# YT9218 register map
Vendor: Motorcomm; Series: YT921x; File version: 1.0
Registers are 32-bit, read-write, no defined reset value unless marked. A register's access mark holds for its fields unless they carry their own. Offsets are from the block's base; [hi:lo] are bit positions; lines under a group give offsets from that group; {n}, {i} and the like mark numbered series; 'fields as' and 'values as' point back to an identical list.

## ACL — ACL keys and control
Base 0x00200000
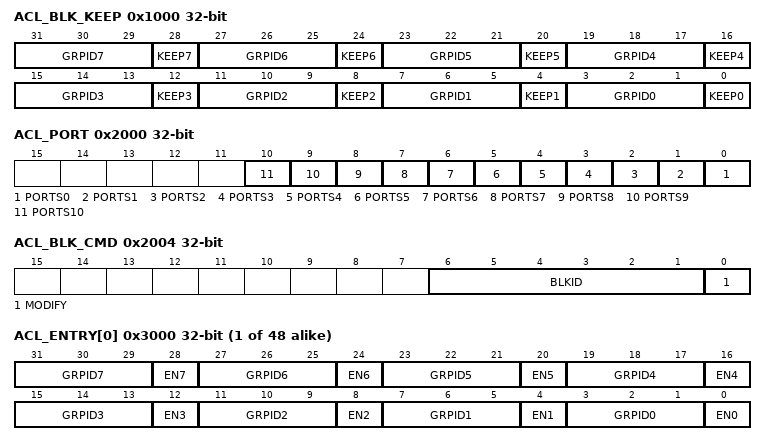
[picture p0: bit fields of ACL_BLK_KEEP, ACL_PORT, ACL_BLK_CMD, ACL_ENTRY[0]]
0x1000 ACL_BLK_KEEP — While a block is open, marks the key slots that the commit must leave unchanged.
  [4n+3:4n+1] GRPID{n} (n=0..7) — Group number for slot bin during the commit.
  [4n] KEEP{n} (n=0..7) — Slot bin keeps its current key and mask.
0x2000 ACL_PORT — Ports whose received frames are checked against the access control list.
  [n] PORTS{n} (n=0..10) — The access control list is applied to port port.
0x2004 ACL_BLK_CMD — Opens one ACL block for modification and commits it; see Writing a rule.
  [6:1] BLKID — Block number from 0 to 47.
  [0] MODIFY — Write 1 to open the block for writing. Write 0 to commit the changes.
{0x3000+4i} ACL_ENTRY[{i}] (i=0..47) — Enables the eight key slots of one block and groups slots into rules. Slots with the same group number must all match for the rule to hit; the group number is also the slot whose ACL_ACT entry holds the action. Index: blk = 0 to 47.
  [4n+3:4n+1] GRPID{n} (n=0..7) — Group number of slot bin. The slots of one rule share a group number.
  [4n] EN{n} (n=0..7) — Slot bin is in use.
{0x4000+0x200*i} ACL_KEY[{i}] (i=0..7) group — Value half of one key slot. Index blk is the block and bin the slot in the block. The layout of bits 35 to 0 and of the range flags depends on ACL_KEY.TYPE. Index: bin = 0 to 7; the member array index is blk.
  {0x0+8j} BLK[{j}] (j=0..47) group — One ACL_KEY entry; index blk = 0 to 47.
    0x00 W0 — ACL key slot: bits 31 to 0. Value half of one key slot. Index blk is the block and bin the slot in the block. The layout of bits 35 to 0 and of the range flags depends on ACL_KEY.TYPE.
    0x00 W0_MAC_ADDR0 (alternate view of W0) — ACL key slot, bits 31 to 0, layout for key types MAC_DA0, MAC_SA0: MAC address high 32 bits
      [31:0] ADDR — MAC address bytes 0 to 3. Byte 0 is in bits 31 to 24.
    0x00 W0_MAC_DA1_SA1 (alternate view of W0) — ACL key slot, bits 31 to 0, layout for key types MAC_DA1_SA1: MAC address low 16 bits of destination and source
      [31:16] MAC_DA1 — Destination MAC address bytes 4 and 5.
      [15:0] MAC_SA1 — Source MAC address bytes 4 and 5.
    0x00 W0_VLAN (alternate view of W0) — ACL key slot, bits 31 to 0, layout for key types VLAN: VLAN tags with tag format
      [31:30] CTAG_FMT — Customer tag format of the frame. The Linux driver gives no codes. The vendor SDK list yt_vlan_format_t gives 0 for untagged, 1 for priority-tagged and 2 for tagged.
      [29] SDEI — Drop eligible bit of the service tag.
      [28:26] SPRI — Priority of the service tag.
      [25:24] STAG_FMT — Service tag format of the frame. The Linux driver gives no codes. The vendor SDK list yt_vlan_format_t gives 0 for untagged, 1 for priority-tagged and 2 for tagged.
      [23:12] SVID — Service VLAN ID.
      [11:0] CVID — Customer VLAN ID.
    0x00 W0_VTAG (alternate view of W0) — ACL key slot, bits 31 to 0, layout for key types VTAG: VLAN tags
      [31] CDEI — Drop eligible bit of the customer tag.
      [30:28] CPRI — Priority of the customer tag.
      [27] SDEI — Drop eligible bit of the service tag.
      [26:24] SPRI — Priority of the service tag.
      [23:12] SVID — Service VLAN ID.
      [11:0] CVID — Customer VLAN ID.
    0x00 W0_IPV4 (alternate view of W0) — ACL key slot, bits 31 to 0, layout for key types IPV4_DA, IPV4_SA: IPv4 address
      [31:0] ADDR — IPv4 address. The first byte is in bits 31 to 24.
    0x00 W0_IPV6_ADDR0 (alternate view of W0) — ACL key slot, bits 31 to 0, layout for key types IPV6_DA0, IPV6_SA0: IPv6 address bits 127 to 96
      [31:0] ADDR — 32 bits of the IPv6 address. The most significant byte is in bits 31 to 24.
    0x00 W0_IPV6_ADDR1 (alternate view of W0) — ACL key slot, bits 31 to 0, layout for key types IPV6_DA1, IPV6_SA1: IPv6 address bits 95 to 64
      fields as ACL_KEY[0].BLK[0].W0_IPV6_ADDR0
    0x00 W0_IPV6_ADDR2 (alternate view of W0) — ACL key slot, bits 31 to 0, layout for key types IPV6_DA2, IPV6_SA2: IPv6 address bits 63 to 32
      fields as ACL_KEY[0].BLK[0].W0_IPV6_ADDR0
    0x00 W0_IPV6_ADDR3 (alternate view of W0) — ACL key slot, bits 31 to 0, layout for key types IPV6_DA3, IPV6_SA3: IPv6 address bits 31 to 0
      fields as ACL_KEY[0].BLK[0].W0_IPV6_ADDR0
    0x00 W0_MISC (alternate view of W0) — ACL key slot, bits 31 to 0, layout for key types MISC: IP header and TCP flags
      [30] PPPOE_FLAG — The frame carries PPPoE.
      [29] FIRST_FRAG — The packet is the first fragment.
      [28] IP_OPTION — The packet has IP options or extension headers.
      [27:20] TCP_FLAGS — TCP flags byte.
      [19:12] IP_PROTO — IP protocol number.
      [11:4] TOS — IPv4 type of service or IPv6 traffic class byte.
      [3:0] L3_TYPE — Layer 3 protocol class.
        0=OTHER (Any other protocol); 1=IPV4; 2=IPV6; 3=ARP; 4=LLDP; 5=PAE (IEEE 802.1X port access entity); 6=ERP (Ethernet ring protection. The meaning is inferred from the name; yt921x_acl_rule_ext_parse_flow_entries selects the value for the EtherType ETH_P_CFM.); 7=SLOW_PROTOCOL (IEEE 802.3 slow protocols such as LACP)
    0x00 W0_L4 (alternate view of W0) — ACL key slot, bits 31 to 0, layout for key types L4: Layer 4 ports
      [31:16] DPORT — Layer 4 destination port.
      [15:0] SPORT — Layer 4 source port.
    0x00 W0_UDF (alternate view of W0) — ACL key slot, bits 31 to 0, layout for key types UDF0, UDF1, UDF2, UDF3, UDF4, UDF5, UDF6, UDF7: User-defined fields
      [31:16] UDF0 — Two bytes from the even-numbered user-defined field window of the pair.
      [15:0] UDF1 — Two bytes from the odd-numbered user-defined field window of the pair.
    0x00 W0_ETHERTYPE (alternate view of W0) — ACL key slot, bits 31 to 0, layout for key types ETHERTYPE: EtherType
      [15:0] ETHERTYPE
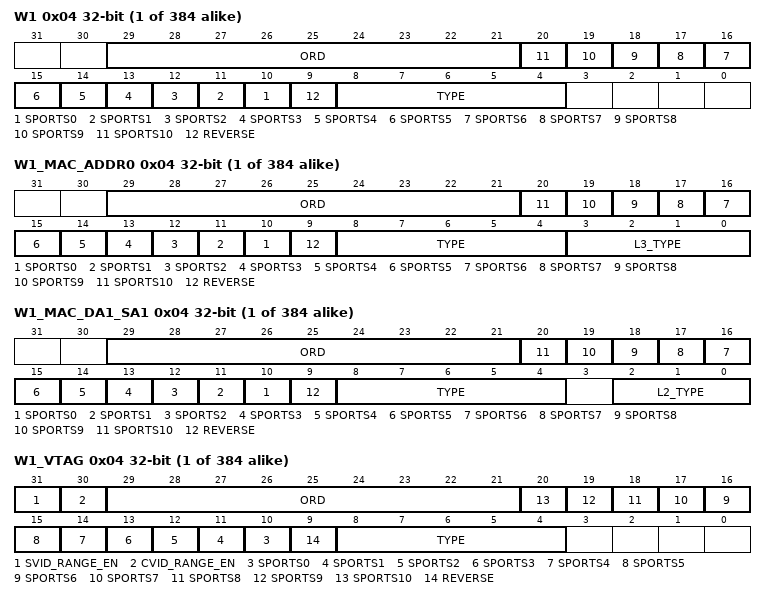
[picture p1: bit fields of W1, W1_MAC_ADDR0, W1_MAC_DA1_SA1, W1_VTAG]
    0x04 W1 — ACL key slot: bits 63 to 32. Value half of one key slot. Index blk is the block and bin the slot in the block. The layout of bits 35 to 0 and of the range flags depends on ACL_KEY.TYPE.
      [29:21] ORD — Order of the rule. When several rules match, the highest value wins.
      [n+10] SPORTS{n} (n=0..10) — Receiving ports the rule applies to. Each port has one bit.
      [9] REVERSE — The slot matches when the frame does not match the key.
      [8:4] TYPE — Key type. It selects the layout of the rest of the slot.
        0=NA (Slot not used); 1=MAC_DA0 (Destination MAC address bits 47 to 16); 2=MAC_SA0 (Source MAC address bits 47 to 16); 3=MAC_DA1_SA1 (Destination and source MAC address bits 15 to 0); 4=VLAN (VLAN identifiers and priorities with tag format); 5=VTAG (VLAN identifiers and priorities); 6=IPV4_DA (IPv4 destination address); 7=IPV4_SA (IPv4 source address); 8=IPV6_DA0 (IPv6 destination address bits 127 to 96); 9=IPV6_DA1 (IPv6 destination address bits 95 to 64); 10=IPV6_DA2 (IPv6 destination address bits 63 to 32); 11=IPV6_DA3 (IPv6 destination address bits 31 to 0); 12=IPV6_SA0 (IPv6 source address bits 127 to 96); 13=IPV6_SA1 (IPv6 source address bits 95 to 64); 14=IPV6_SA2 (IPv6 source address bits 63 to 32); 15=IPV6_SA3 (IPv6 source address bits 31 to 0); 16=MISC (IP and TCP header fields. The fields are the IP protocol and the type of service and the TCP flags and the frame class); 17=L4 (TCP or UDP source and destination ports); 18=UDF0 (User-defined field windows 0 and 1); 19=UDF1 (User-defined field windows 2 and 3); 20=UDF2 (User-defined field windows 4 and 5); 21=UDF3 (User-defined field windows 6 and 7); 22=UDF4 (User-defined field windows 8 and 9); 23=UDF5 (User-defined field windows 10 and 11); 24=UDF6 (User-defined field windows 12 and 13); 25=UDF7 (User-defined field windows 14 and 15); 26=ETHERTYPE
    0x04 W1_MAC_ADDR0 (alternate view of W1) — ACL key slot, bits 63 to 32, layout for key types MAC_DA0, MAC_SA0: MAC address high 32 bits
      [29:21] ORD — Order of the rule. When several rules match, the highest value wins.
      [n+10] SPORTS{n} (n=0..10) — Receiving ports the rule applies to. Each port has one bit.
      [9] REVERSE — The slot matches when the frame does not match the key.
      [8:4] TYPE — Key type. It selects the layout of the rest of the slot.
        values as ACL_KEY[0].BLK[0].W1.TYPE
      [3:0] L3_TYPE — Layer 3 protocol class.
        values as ACL_KEY[0].BLK[0].W0_MISC.L3_TYPE
    0x04 W1_MAC_DA1_SA1 (alternate view of W1) — ACL key slot, bits 63 to 32, layout for key types MAC_DA1_SA1: MAC address low 16 bits of destination and source
      [29:21] ORD — Order of the rule. When several rules match, the highest value wins.
      [n+10] SPORTS{n} (n=0..10) — Receiving ports the rule applies to. Each port has one bit.
      [9] REVERSE — The slot matches when the frame does not match the key.
      [8:4] TYPE — Key type. It selects the layout of the rest of the slot.
        values as ACL_KEY[0].BLK[0].W1.TYPE
      [2:0] L2_TYPE — Frame encapsulation.
        0=ETH (Other Ethernet framing. The meaning is inferred from the name.); 1=ETHV2 (Ethernet II); 2=ETHSAP (IEEE 802.3 with LLC); 3=ETHSNAP (IEEE 802.3 with LLC and SNAP)
    0x04 W1_VLAN (alternate view of W1) — ACL key slot, bits 63 to 32, layout for key types VLAN: VLAN tags with tag format
      [31] SVID_RANGE_EN — Match the service VLAN ID as a range. It is inferred from the two layer 4 port range flags, which yt921x_acl_rule_ext_parse_flow_entries uses, that the key holds the lowest and the mask the highest value.
      [30] CVID_RANGE_EN — Match the customer VLAN ID as a range. It is inferred from the two layer 4 port range flags, which yt921x_acl_rule_ext_parse_flow_entries uses, that the key holds the lowest and the mask the highest value.
      [29:21] ORD — Order of the rule. When several rules match, the highest value wins.
      [n+10] SPORTS{n} (n=0..10) — Receiving ports the rule applies to. Each port has one bit.
      [9] REVERSE — The slot matches when the frame does not match the key.
      [8:4] TYPE — Key type. It selects the layout of the rest of the slot.
        values as ACL_KEY[0].BLK[0].W1.TYPE
      [3] CDEI — Drop eligible bit of the customer tag.
      [2:0] CPRI — Priority of the customer tag.
    0x04 W1_VTAG (alternate view of W1) — ACL key slot, bits 63 to 32, layout for key types VTAG: VLAN tags
      [31] SVID_RANGE_EN — Match the service VLAN ID as a range. It is inferred from the two layer 4 port range flags, which yt921x_acl_rule_ext_parse_flow_entries uses, that the key holds the lowest and the mask the highest value.
      [30] CVID_RANGE_EN — Match the customer VLAN ID as a range. It is inferred from the two layer 4 port range flags, which yt921x_acl_rule_ext_parse_flow_entries uses, that the key holds the lowest and the mask the highest value.
      [29:21] ORD — Order of the rule. When several rules match, the highest value wins.
      [n+10] SPORTS{n} (n=0..10) — Receiving ports the rule applies to. Each port has one bit.
      [9] REVERSE — The slot matches when the frame does not match the key.
      [8:4] TYPE — Key type. It selects the layout of the rest of the slot.
        values as ACL_KEY[0].BLK[0].W1.TYPE
    0x04 W1_IPV4 (alternate view of W1) — ACL key slot, bits 63 to 32, layout for key types IPV4_DA, IPV4_SA: IPv4 address
      [30] ADDR_RANGE_EN — Match the address as a range. It is inferred from the two layer 4 port range flags, which yt921x_acl_rule_ext_parse_flow_entries uses, that the key holds the lowest and the mask the highest value.
      [29:21] ORD — Order of the rule. When several rules match, the highest value wins.
      [n+10] SPORTS{n} (n=0..10) — Receiving ports the rule applies to. Each port has one bit.
      [9] REVERSE — The slot matches when the frame does not match the key.
      [8:4] TYPE — Key type. It selects the layout of the rest of the slot.
        values as ACL_KEY[0].BLK[0].W1.TYPE
      [3] FRAG — The packet is an IP fragment.
      [2:0] L4_TYPE — Layer 4 protocol class.
        0=OTHER (Any other protocol); 1=TCP; 2=UDP; 3=UDPLITE; 4=ICMP; 5=IGMP; 6=MLD (Multicast Listener Discovery); 7=ND (IPv6 Neighbour Discovery)
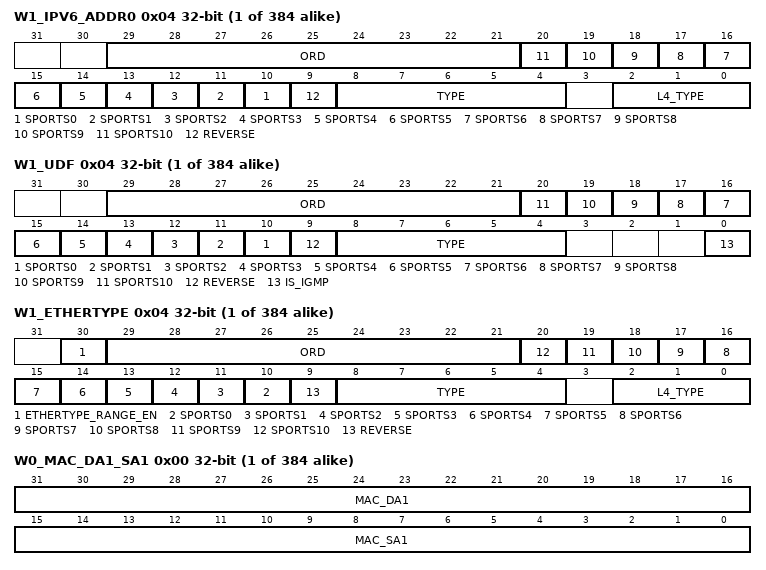
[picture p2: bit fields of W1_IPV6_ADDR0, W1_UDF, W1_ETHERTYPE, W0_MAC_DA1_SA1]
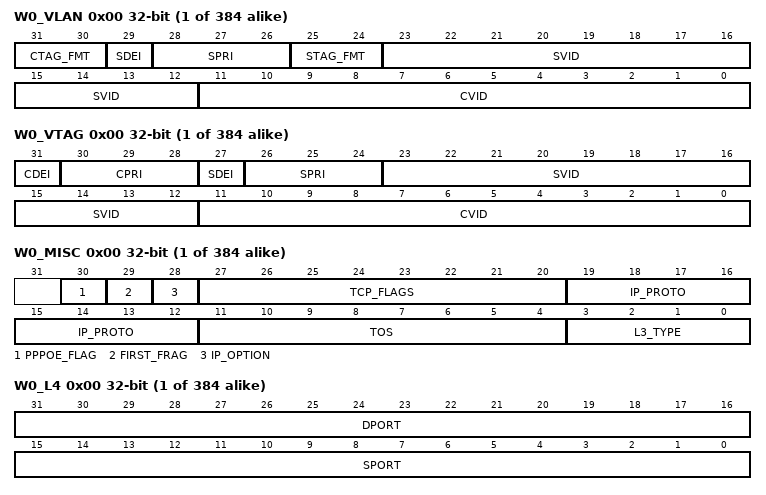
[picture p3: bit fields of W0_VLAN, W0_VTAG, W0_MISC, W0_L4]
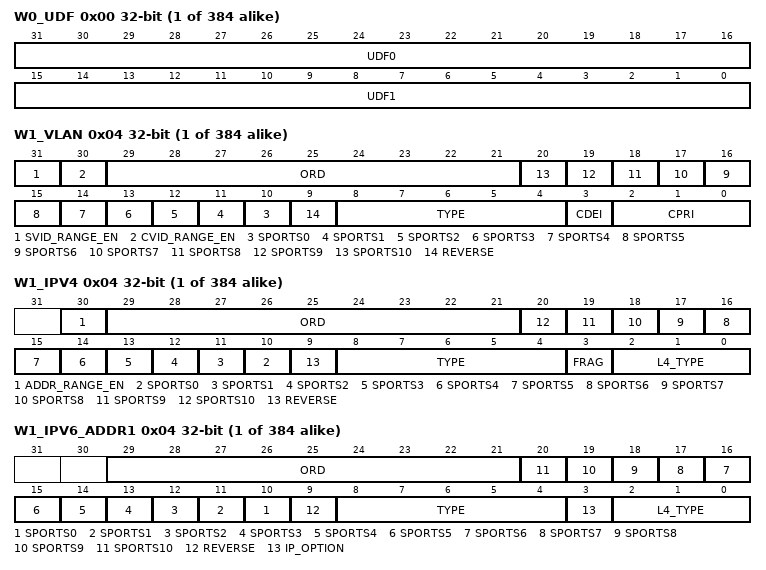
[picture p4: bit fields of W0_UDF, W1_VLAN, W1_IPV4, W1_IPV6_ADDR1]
    0x04 W1_IPV6_ADDR0 (alternate view of W1) — ACL key slot, bits 63 to 32, layout for key types IPV6_DA0, IPV6_SA0: IPv6 address bits 127 to 96
      [29:21] ORD — Order of the rule. When several rules match, the highest value wins.
      [n+10] SPORTS{n} (n=0..10) — Receiving ports the rule applies to. Each port has one bit.
      [9] REVERSE — The slot matches when the frame does not match the key.
      [8:4] TYPE — Key type. It selects the layout of the rest of the slot.
        values as ACL_KEY[0].BLK[0].W1.TYPE
      [2:0] L4_TYPE — Layer 4 protocol class.
        values as ACL_KEY[0].BLK[0].W1_IPV4.L4_TYPE
    0x04 W1_IPV6_ADDR1 (alternate view of W1) — ACL key slot, bits 63 to 32, layout for key types IPV6_DA1, IPV6_SA1: IPv6 address bits 95 to 64
      [29:21] ORD — Order of the rule. When several rules match, the highest value wins.
      [n+10] SPORTS{n} (n=0..10) — Receiving ports the rule applies to. Each port has one bit.
      [9] REVERSE — The slot matches when the frame does not match the key.
      [8:4] TYPE — Key type. It selects the layout of the rest of the slot.
        values as ACL_KEY[0].BLK[0].W1.TYPE
      [3] IP_OPTION — The packet has IP options or extension headers.
      [2:0] L4_TYPE — Layer 4 protocol class.
        values as ACL_KEY[0].BLK[0].W1_IPV4.L4_TYPE
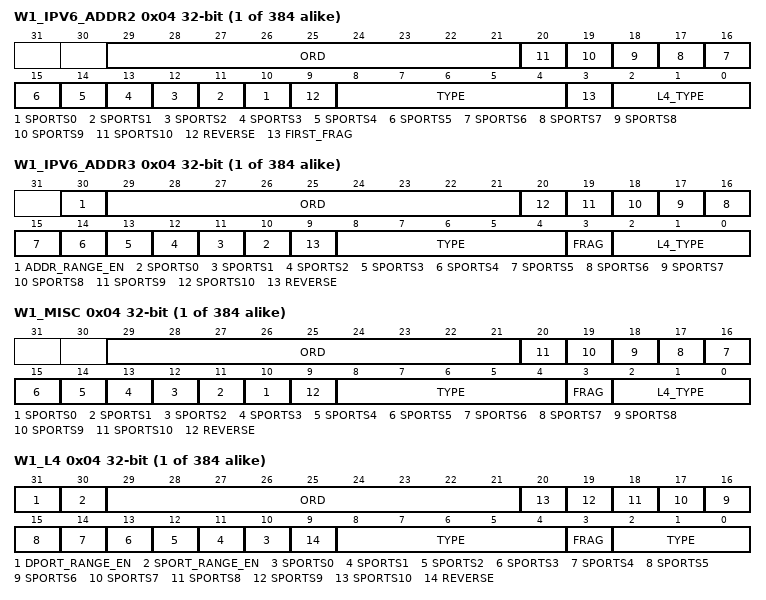
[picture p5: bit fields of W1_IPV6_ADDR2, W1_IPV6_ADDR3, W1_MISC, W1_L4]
    0x04 W1_IPV6_ADDR2 (alternate view of W1) — ACL key slot, bits 63 to 32, layout for key types IPV6_DA2, IPV6_SA2: IPv6 address bits 63 to 32
      [29:21] ORD — Order of the rule. When several rules match, the highest value wins.
      [n+10] SPORTS{n} (n=0..10) — Receiving ports the rule applies to. Each port has one bit.
      [9] REVERSE — The slot matches when the frame does not match the key.
      [8:4] TYPE — Key type. It selects the layout of the rest of the slot.
        values as ACL_KEY[0].BLK[0].W1.TYPE
      [3] FIRST_FRAG — The packet is the first fragment.
      [2:0] L4_TYPE — Layer 4 protocol class.
        values as ACL_KEY[0].BLK[0].W1_IPV4.L4_TYPE
    0x04 W1_IPV6_ADDR3 (alternate view of W1) — ACL key slot, bits 63 to 32, layout for key types IPV6_DA3, IPV6_SA3: IPv6 address bits 31 to 0
      fields as ACL_KEY[0].BLK[0].W1_IPV4
    0x04 W1_MISC (alternate view of W1) — ACL key slot, bits 63 to 32, layout for key types MISC: IP header and TCP flags
      [29:21] ORD — Order of the rule. When several rules match, the highest value wins.
      [n+10] SPORTS{n} (n=0..10) — Receiving ports the rule applies to. Each port has one bit.
      [9] REVERSE — The slot matches when the frame does not match the key.
      [8:4] TYPE — Key type. It selects the layout of the rest of the slot.
        values as ACL_KEY[0].BLK[0].W1.TYPE
      [3] FRAG — The packet is an IP fragment.
      [2:0] L4_TYPE — Layer 4 protocol class.
        values as ACL_KEY[0].BLK[0].W1_IPV4.L4_TYPE
    0x04 W1_L4 (alternate view of W1) — ACL key slot, bits 63 to 32, layout for key types L4: Layer 4 ports
      [31] DPORT_RANGE_EN — Match the destination port as a range. The key holds the lowest and the mask the highest value.
      [30] SPORT_RANGE_EN — Match the source port as a range. The key holds the lowest and the mask the highest value.
      [29:21] ORD — Order of the rule. When several rules match, the highest value wins.
      [n+10] SPORTS{n} (n=0..10) — Receiving ports the rule applies to. Each port has one bit.
      [9] REVERSE — The slot matches when the frame does not match the key.
      [8:4] TYPE — Key type. It selects the layout of the rest of the slot.
        values as ACL_KEY[0].BLK[0].W1.TYPE
      [3] FRAG — The packet is an IP fragment.
      [2:0] TYPE — Layer 4 protocol class.
        values as ACL_KEY[0].BLK[0].W1_IPV4.L4_TYPE
    0x04 W1_UDF (alternate view of W1) — ACL key slot, bits 63 to 32, layout for key types UDF0, UDF1, UDF2, UDF3, UDF4, UDF5, UDF6, UDF7: User-defined fields
      [29:21] ORD — Order of the rule. When several rules match, the highest value wins.
      [n+10] SPORTS{n} (n=0..10) — Receiving ports the rule applies to. Each port has one bit.
      [9] REVERSE — The slot matches when the frame does not match the key.
      [8:4] TYPE — Key type. It selects the layout of the rest of the slot.
        values as ACL_KEY[0].BLK[0].W1.TYPE
      [0] IS_IGMP — The frame is an IGMP message.
    0x04 W1_ETHERTYPE (alternate view of W1) — ACL key slot, bits 63 to 32, layout for key types ETHERTYPE: EtherType
      [30] ETHERTYPE_RANGE_EN — Match the EtherType as a range. It is inferred from the two layer 4 port range flags, which yt921x_acl_rule_ext_parse_flow_entries uses, that the key holds the lowest and the mask the highest value.
      [29:21] ORD — Order of the rule. When several rules match, the highest value wins.
      [n+10] SPORTS{n} (n=0..10) — Receiving ports the rule applies to. Each port has one bit.
      [9] REVERSE — The slot matches when the frame does not match the key.
      [8:4] TYPE — Key type. It selects the layout of the rest of the slot.
        values as ACL_KEY[0].BLK[0].W1.TYPE
      [2:0] L4_TYPE — Layer 4 protocol class.
        values as ACL_KEY[0].BLK[0].W1_IPV4.L4_TYPE
{0x5000+0x200*i} ACL_MASK[{i}] (i=0..7) group — Mask half of one key slot. A set bit means the same bit of ACL_KEY must match; the layouts are those of the key. For a field matched as a range the mask holds the highest value. Index: bin = 0 to 7; the member array index is blk.
  {0x0+8j} BLK[{j}] (j=0..47) group — One ACL_MASK entry; index blk = 0 to 47.
    0x00 W0 — ACL mask slot: bits 31 to 0. Mask half of one key slot. A set bit means the same bit of ACL_KEY must match; the layouts are those of the key. For a field matched as a range the mask holds the highest value.
    0x00 W0_MAC_ADDR0 (alternate view of W0) — ACL mask slot, bits 31 to 0, layout for key types MAC_DA0, MAC_SA0: MAC address high 32 bits
      [31:0] ADDR — MAC address bytes 0 to 3. Byte 0 is in bits 31 to 24.
    0x00 W0_MAC_DA1_SA1 (alternate view of W0) — ACL mask slot, bits 31 to 0, layout for key types MAC_DA1_SA1: MAC address low 16 bits of destination and source
      fields as ACL_KEY[0].BLK[0].W0_MAC_DA1_SA1
    0x00 W0_VLAN (alternate view of W0) — ACL mask slot, bits 31 to 0, layout for key types VLAN: VLAN tags with tag format
      fields as ACL_KEY[0].BLK[0].W0_VLAN
    0x00 W0_VTAG (alternate view of W0) — ACL mask slot, bits 31 to 0, layout for key types VTAG: VLAN tags
      fields as ACL_KEY[0].BLK[0].W0_VTAG
    0x00 W0_IPV4 (alternate view of W0) — ACL mask slot, bits 31 to 0, layout for key types IPV4_DA, IPV4_SA: IPv4 address
      [31:0] ADDR — IPv4 address. The first byte is in bits 31 to 24.
    0x00 W0_IPV6_ADDR0 (alternate view of W0) — ACL mask slot, bits 31 to 0, layout for key types IPV6_DA0, IPV6_SA0: IPv6 address bits 127 to 96
      fields as ACL_KEY[0].BLK[0].W0_IPV6_ADDR0
    0x00 W0_IPV6_ADDR1 (alternate view of W0) — ACL mask slot, bits 31 to 0, layout for key types IPV6_DA1, IPV6_SA1: IPv6 address bits 95 to 64
      fields as ACL_KEY[0].BLK[0].W0_IPV6_ADDR0
    0x00 W0_IPV6_ADDR2 (alternate view of W0) — ACL mask slot, bits 31 to 0, layout for key types IPV6_DA2, IPV6_SA2: IPv6 address bits 63 to 32
      fields as ACL_KEY[0].BLK[0].W0_IPV6_ADDR0
    0x00 W0_IPV6_ADDR3 (alternate view of W0) — ACL mask slot, bits 31 to 0, layout for key types IPV6_DA3, IPV6_SA3: IPv6 address bits 31 to 0
      fields as ACL_KEY[0].BLK[0].W0_IPV6_ADDR0
    0x00 W0_MISC (alternate view of W0) — ACL mask slot, bits 31 to 0, layout for key types MISC: IP header and TCP flags
      fields as ACL_KEY[0].BLK[0].W0_MISC
    0x00 W0_L4 (alternate view of W0) — ACL mask slot, bits 31 to 0, layout for key types L4: Layer 4 ports
      fields as ACL_KEY[0].BLK[0].W0_L4
    0x00 W0_UDF (alternate view of W0) — ACL mask slot, bits 31 to 0, layout for key types UDF0, UDF1, UDF2, UDF3, UDF4, UDF5, UDF6, UDF7: User-defined fields
      fields as ACL_KEY[0].BLK[0].W0_UDF
    0x00 W0_ETHERTYPE (alternate view of W0) — ACL mask slot, bits 31 to 0, layout for key types ETHERTYPE: EtherType
      [15:0] ETHERTYPE
    0x04 W1 — ACL mask slot: bits 63 to 32. Mask half of one key slot. A set bit means the same bit of ACL_KEY must match; the layouts are those of the key. For a field matched as a range the mask holds the highest value.
    0x04 W1_MAC_ADDR0 (alternate view of W1) — ACL mask slot, bits 63 to 32, layout for key types MAC_DA0, MAC_SA0: MAC address high 32 bits
      [3:0] L3_TYPE — Layer 3 protocol class.
        values as ACL_KEY[0].BLK[0].W0_MISC.L3_TYPE
    0x04 W1_MAC_DA1_SA1 (alternate view of W1) — ACL mask slot, bits 63 to 32, layout for key types MAC_DA1_SA1: MAC address low 16 bits of destination and source
      [2:0] L2_TYPE — Frame encapsulation.
        values as ACL_KEY[0].BLK[0].W1_MAC_DA1_SA1.L2_TYPE
    0x04 W1_VLAN (alternate view of W1) — ACL mask slot, bits 63 to 32, layout for key types VLAN: VLAN tags with tag format
      [3] CDEI — Drop eligible bit of the customer tag.
      [2:0] CPRI — Priority of the customer tag.
    0x04 W1_IPV4 (alternate view of W1) — ACL mask slot, bits 63 to 32, layout for key types IPV4_DA, IPV4_SA: IPv4 address
      [3] FRAG — The packet is an IP fragment.
      [2:0] L4_TYPE — Layer 4 protocol class.
        values as ACL_KEY[0].BLK[0].W1_IPV4.L4_TYPE
    0x04 W1_IPV6_ADDR0 (alternate view of W1) — ACL mask slot, bits 63 to 32, layout for key types IPV6_DA0, IPV6_SA0: IPv6 address bits 127 to 96
      [2:0] L4_TYPE — Layer 4 protocol class.
        values as ACL_KEY[0].BLK[0].W1_IPV4.L4_TYPE
    0x04 W1_IPV6_ADDR1 (alternate view of W1) — ACL mask slot, bits 63 to 32, layout for key types IPV6_DA1, IPV6_SA1: IPv6 address bits 95 to 64
      [3] IP_OPTION — The packet has IP options or extension headers.
      [2:0] L4_TYPE — Layer 4 protocol class.
        values as ACL_KEY[0].BLK[0].W1_IPV4.L4_TYPE
    0x04 W1_IPV6_ADDR2 (alternate view of W1) — ACL mask slot, bits 63 to 32, layout for key types IPV6_DA2, IPV6_SA2: IPv6 address bits 63 to 32
      [3] FIRST_FRAG — The packet is the first fragment.
      [2:0] L4_TYPE — Layer 4 protocol class.
        values as ACL_KEY[0].BLK[0].W1_IPV4.L4_TYPE
    0x04 W1_IPV6_ADDR3 (alternate view of W1) — ACL mask slot, bits 63 to 32, layout for key types IPV6_DA3, IPV6_SA3: IPv6 address bits 31 to 0
      fields as ACL_MASK[0].BLK[0].W1_IPV4
    0x04 W1_MISC (alternate view of W1) — ACL mask slot, bits 63 to 32, layout for key types MISC: IP header and TCP flags
      fields as ACL_MASK[0].BLK[0].W1_IPV4
    0x04 W1_L4 (alternate view of W1) — ACL mask slot, bits 63 to 32, layout for key types L4: Layer 4 ports
      [3] FRAG — The packet is an IP fragment.
      [2:0] TYPE — Layer 4 protocol class.
        values as ACL_KEY[0].BLK[0].W1_IPV4.L4_TYPE
    0x04 W1_UDF (alternate view of W1) — ACL mask slot, bits 63 to 32, layout for key types UDF0, UDF1, UDF2, UDF3, UDF4, UDF5, UDF6, UDF7: User-defined fields
      [0] IS_IGMP — The frame is an IGMP message.
    0x04 W1_ETHERTYPE (alternate view of W1) — ACL mask slot, bits 63 to 32, layout for key types ETHERTYPE: EtherType
      fields as ACL_MASK[0].BLK[0].W1_IPV6_ADDR0
